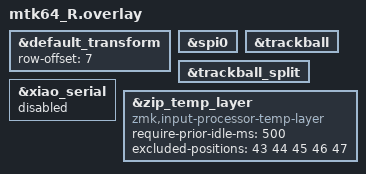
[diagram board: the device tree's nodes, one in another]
#include "mtk64.dtsi"
#include "mtk64_trackball.dtsi"

&default_transform {
    row-offset = <7>;
};

/*
&kscan0 {
    gpios
        = <&xiao_d 1 GPIO_ACTIVE_HIGH> 
        , <&xiao_d 2 GPIO_ACTIVE_HIGH> 
        , <&xiao_d 3 GPIO_ACTIVE_HIGH> 
        , <&xiao_d 6 GPIO_ACTIVE_HIGH>
        , <&xiao_d 7 GPIO_ACTIVE_HIGH> 
        , <&xiao_d 8 GPIO_ACTIVE_HIGH> 
        , <&xiao_d 9 GPIO_ACTIVE_HIGH> 	
    ;
};
*/

&spi0 {
    status = "okay";
};

&trackball { 
    status = "okay";
};

&trackball_split { 
    status = "okay";
};



&xiao_serial { status = "disabled"; };



#include <input/processors.dtsi>

&zip_temp_layer {
    compatible = "zmk,input-processor-temp-layer";
    #input-processor-cells = <2>;
    require-prior-idle-ms = <500>;
    excluded-positions = <43 44 45 46 47>; // ],N,M,<,> 
};


